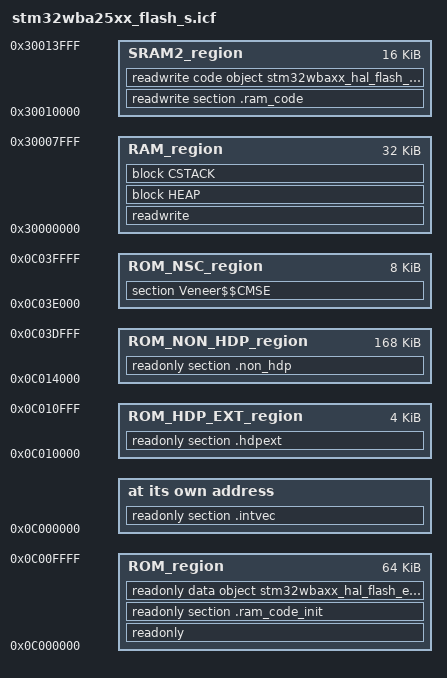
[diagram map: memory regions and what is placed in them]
/*###ICF### Section handled by ICF editor, don't touch! ****/
/*-Editor annotation file-*/
/* IcfEditorFile="$TOOLKIT_DIR$\config\ide\IcfEditor\cortex_v1_0.xml" */
/*-Specials-*/
define symbol __ICFEDIT_intvec_start__ = 0x0C000000;
/*-Memory Regions-*/
define symbol __ICFEDIT_region_ROM_start__ = 0x0C000000;
define symbol __ICFEDIT_region_ROM_end__   = 0x0C00FFFF;
define symbol __region_ROM_HDP_EXT_start__ = 0x0C010000;
define symbol __region_ROM_HDP_EXT_end__   = 0x0C010FFF;
define symbol __region_ROM_NON_HDP_start__ = 0x0C014000;
define symbol __region_ROM_NON_HDP_end__   = 0x0C03DFFF;
define symbol __region_ROM_NSC_start__ 	   = 0x0C03E000;
define symbol __region_ROM_NSC_end__       = 0x0C03FFFF;
define symbol __region_ROM_NS_start__      = 0x08040000;
define symbol __region_ROM_NS_end__        = 0x0807FFFF;
define symbol __ICFEDIT_region_RAM_start__ = 0x30000000;
define symbol __ICFEDIT_region_RAM_end__   = 0x30007FFF;
define symbol __region_SRAM2_start__       = 0x30010000;
define symbol __region_SRAM2_end__         = 0x30013FFF;

/*-Sizes-*/
define symbol __ICFEDIT_size_cstack__ = 0x400;
define symbol __ICFEDIT_size_heap__   = 0x200;
/**** End of ICF editor section. ###ICF###*/

define memory mem with size = 4G;
define region ROM_region      = mem:[from __ICFEDIT_region_ROM_start__      to __ICFEDIT_region_ROM_end__];
define region ROM_HDP_EXT_region = mem:[from __region_ROM_HDP_EXT_start__ to __region_ROM_HDP_EXT_end__];
define region ROM_NON_HDP_region = mem:[from __region_ROM_NON_HDP_start__ to __region_ROM_NON_HDP_end__];
define region ROM_NSC_region  = mem:[from __region_ROM_NSC_start__          to __region_ROM_NSC_end__];
define region RAM_region      = mem:[from __ICFEDIT_region_RAM_start__      to __ICFEDIT_region_RAM_end__];
define region SRAM2_region    = mem:[from __region_SRAM2_start__            to __region_SRAM2_end__];

define exported symbol __VTOR_TABLE_start       = __ICFEDIT_intvec_start__;
define exported symbol __VTOR_TABLE_NS_start    = __region_ROM_NS_start__;
define exported symbol __NSC_region_start       = __region_ROM_NSC_start__;
define exported symbol __NSC_region_end         = __region_ROM_NSC_end__;

define block CSTACK    with alignment = 8, size = __ICFEDIT_size_cstack__   { };
define block HEAP      with alignment = 8, size = __ICFEDIT_size_heap__     { };

initialize by copy { readwrite, readonly section .ram_code, readonly code object stm32wbaxx_hal_flash_ex.o };
do not initialize  { section .noinit };

place at address mem:__ICFEDIT_intvec_start__ { readonly section .intvec };

place in ROM_region         { readonly, readonly section .ram_code_init, readonly data object stm32wbaxx_hal_flash_ex.o };
place in ROM_HDP_EXT_region { readonly section .hdpext };
place in ROM_NON_HDP_region { readonly section .non_hdp };
place in ROM_NSC_region     { section Veneer$$CMSE };
place in RAM_region         { readwrite,
                              block HEAP, block CSTACK };
place in SRAM2_region       { readwrite section .ram_code, readwrite code object stm32wbaxx_hal_flash_ex.o };

export symbol __ICFEDIT_region_ROM_start__;
export symbol __ICFEDIT_region_ROM_end__;
export symbol __region_ROM_NS_start__;
export symbol __region_ROM_NS_end__;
